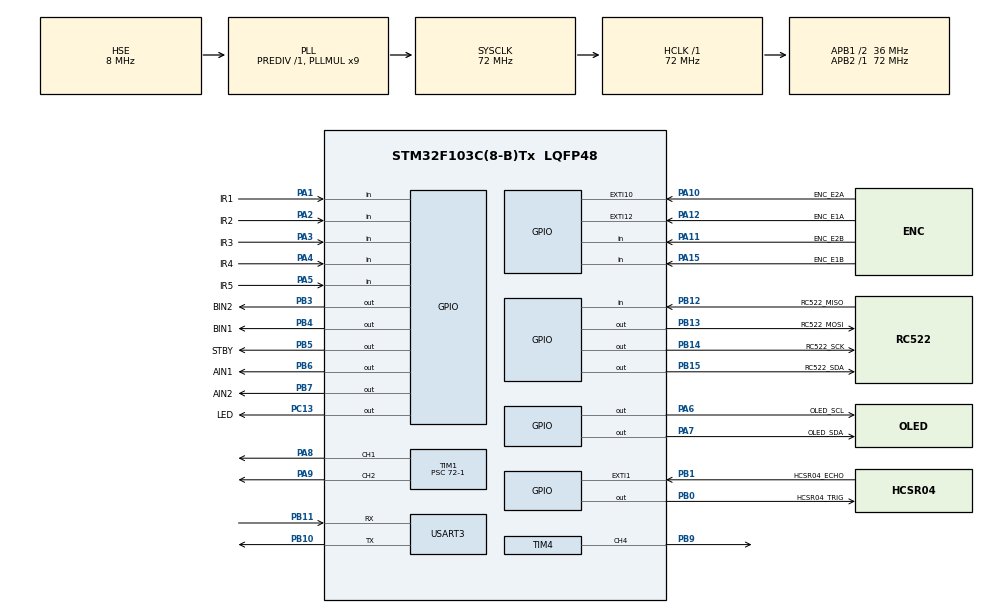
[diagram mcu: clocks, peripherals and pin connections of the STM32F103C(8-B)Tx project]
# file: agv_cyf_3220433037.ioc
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Mcu.Family=STM32F1
Mcu.Name=STM32F103C(8-B)Tx
Mcu.Package=LQFP48
NVIC.EXTI1_IRQn=true\:1\:0\:false\:false\:true\:true\:false\:false
NVIC.EXTI15_10_IRQn=true\:2\:0\:false\:false\:true\:true\:false\:false
NVIC.PriorityGroup=NVIC_PRIORITYGROUP_4
NVIC.USART3_IRQn=true\:1\:0\:false\:false\:true\:true\:false\:false
PA1.GPIO_Label=IR1
PA1.GPIO_PuPd=GPIO_PULLUP
PA1.Signal=GPIO_Input
PA10.GPIO_Label=ENC_E2A
PA10.GPIO_ModeDefaultEXTI=GPIO_MODE_IT_RISING_FALLING
PA10.GPIO_PuPd=GPIO_PULLUP
PA10.Signal=GPXTI10
PA11.GPIO_Label=ENC_E2B
PA11.GPIO_PuPd=GPIO_PULLUP
PA11.Signal=GPIO_Input
PA12.GPIO_Label=ENC_E1A
PA12.GPIO_ModeDefaultEXTI=GPIO_MODE_IT_RISING_FALLING
PA12.GPIO_PuPd=GPIO_PULLUP
PA12.Signal=GPXTI12
PA13.Mode=Serial_Wire
PA13.Signal=SYS_JTMS-SWDIO
PA14.Mode=Serial_Wire
PA14.Signal=SYS_JTCK-SWCLK
PA15.GPIO_Label=ENC_E1B
PA15.GPIO_PuPd=GPIO_PULLUP
PA15.Signal=GPIO_Input
PA2.GPIO_Label=IR2
PA2.GPIO_PuPd=GPIO_PULLUP
PA2.Signal=GPIO_Input
PA3.GPIO_Label=IR3
PA3.GPIO_PuPd=GPIO_PULLUP
PA3.Signal=GPIO_Input
PA4.GPIO_Label=IR4
PA4.GPIO_PuPd=GPIO_PULLUP
PA4.Signal=GPIO_Input
PA5.GPIO_Label=IR5
PA5.GPIO_PuPd=GPIO_PULLUP
PA5.Signal=GPIO_Input
PA6.GPIO_Label=OLED_SCL
PA6.GPIO_ModeDefaultOutputPP=GPIO_MODE_OUTPUT_OD
PA6.GPIO_PuPd=GPIO_PULLUP
PA6.PinState=GPIO_PIN_SET
PA6.Signal=GPIO_Output
PA7.GPIO_Label=OLED_SDA
PA7.GPIO_ModeDefaultOutputPP=GPIO_MODE_OUTPUT_OD
PA7.GPIO_PuPd=GPIO_PULLUP
PA7.PinState=GPIO_PIN_SET
PA7.Signal=GPIO_Output
PA8.Signal=S_TIM1_CH1
PA9.Signal=S_TIM1_CH2
PB0.GPIO_Label=HCSR04_TRIG
PB0.Signal=GPIO_Output
PB1.GPIO_Label=HCSR04_ECHO
PB1.GPIO_ModeDefaultEXTI=GPIO_MODE_IT_RISING_FALLING
PB1.GPIO_PuPd=GPIO_NOPULL
PB1.Signal=GPXTI1
PB10.Mode=Asynchronous
PB10.Signal=USART3_TX
PB11.Mode=Asynchronous
PB11.Signal=USART3_RX
PB12.GPIO_Label=RC522_MISO
PB12.GPIO_PuPd=GPIO_NOPULL
PB12.Signal=GPIO_Input
PB13.GPIO_Label=RC522_MOSI
PB13.GPIO_ModeDefaultOutputPP=GPIO_MODE_OUTPUT_PP
PB13.GPIO_PuPd=GPIO_NOPULL
PB13.PinState=GPIO_PIN_RESET
PB13.Signal=GPIO_Output
PB14.GPIO_Label=RC522_SCK
PB14.GPIO_ModeDefaultOutputPP=GPIO_MODE_OUTPUT_PP
PB14.GPIO_PuPd=GPIO_NOPULL
PB14.PinState=GPIO_PIN_RESET
PB14.Signal=GPIO_Output
PB15.GPIO_Label=RC522_SDA
PB15.GPIO_ModeDefaultOutputPP=GPIO_MODE_OUTPUT_PP
PB15.GPIO_PuPd=GPIO_NOPULL
PB15.PinState=GPIO_PIN_SET
PB15.Signal=GPIO_Output
PB3.GPIO_Label=BIN2
PB3.Signal=GPIO_Output
PB4.GPIO_Label=BIN1
PB4.Signal=GPIO_Output
PB5.GPIO_Label=STBY
PB5.Signal=GPIO_Output
PB6.GPIO_Label=AIN1
PB6.Signal=GPIO_Output
PB7.GPIO_Label=AIN2
PB7.Signal=GPIO_Output
PB9.Signal=S_TIM4_CH4
PC13-TAMPER-RTC.GPIO_Label=LED
PC13-TAMPER-RTC.GPIO_ModeDefaultOutputPP=GPIO_MODE_OUTPUT_PP
PC13-TAMPER-RTC.GPIO_PuPd=GPIO_NOPULL
PC13-TAMPER-RTC.PinState=GPIO_PIN_SET
PC13-TAMPER-RTC.Signal=GPIO_Output
PD0-OSC_IN.Mode=HSE-External-Oscillator
PD0-OSC_IN.Signal=RCC_OSC_IN
PD1-OSC_OUT.Mode=HSE-External-Oscillator
PD1-OSC_OUT.Signal=RCC_OSC_OUT
ProjectManager.HeapSize=0x200
ProjectManager.StackSize=0x400
ProjectManager.TargetToolchain=MDK-ARM V5.32
RCC.AHBFreq_Value=72000000
RCC.APB1CLKDivider=RCC_HCLK_DIV2
RCC.APB1Freq_Value=36000000
RCC.APB1TimFreq_Value=72000000
RCC.APB2Freq_Value=72000000
RCC.APB2TimFreq_Value=72000000
RCC.HCLKFreq_Value=72000000
RCC.PLLMUL=RCC_PLL_MUL9
RCC.PLLSourceVirtual=RCC_PLLSOURCE_HSE
RCC.SYSCLKFreq_VALUE=72000000
RCC.SYSCLKSource=RCC_SYSCLKSOURCE_PLLCLK
RCC.USBFreq_Value=72000000
SH.S_TIM1_CH1.0=TIM1_CH1,PWM Generation1 CH1
SH.S_TIM1_CH2.0=TIM1_CH2,PWM Generation2 CH2
SH.S_TIM4_CH4.0=TIM4_CH4,PWM Generation4 CH4
TIM1.Channel-PWM\ Generation1\ CH1=TIM_CHANNEL_1
TIM1.Channel-PWM\ Generation2\ CH2=TIM_CHANNEL_2
TIM1.Period=1000-1
TIM1.Prescaler=72-1
TIM2.Period=65535
TIM2.Prescaler=72-1
TIM4.Channel-PWM\ Generation4\ CH4=TIM_CHANNEL_4
TIM4.Period=20000-1
TIM4.Prescaler=72-1
USART3.VirtualMode=VM_ASYNC
VP_TIM1_VS_ClockSourceINT.Mode=Internal
VP_TIM2_VS_ClockSourceINT.Mode=Internal
VP_TIM4_VS_ClockSourceINT.Mode=Internal
board=custom

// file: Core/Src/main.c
/* USER CODE BEGIN Header */
/**
  ******************************************************************************
  * @file           : main.c
  * @brief          : Main program body
  ******************************************************************************
  * @attention
  *
  * Copyright (c) 2026 STMicroelectronics.
  * All rights reserved.
  *
  * This software is licensed under terms that can be found in the LICENSE file
  * in the root directory of this software component.
  * If no LICENSE file comes with this software, it is provided AS-IS.
  *
  ******************************************************************************
  */
/* USER CODE END Header */
#include "main.h"
#include "tim.h"
#include "usart.h"
#include "gpio.h"

/* USER CODE BEGIN Includes */
#include "app_encoder.h"
#include "app_ultrasonic.h"
#include "app_vehicle.h"
/*
 * main.c 的职责很单一：
 * 1. 完成 HAL、时钟和基础外设初始化；
 * 2. 初始化上层整车应用模块；
 * 3. 在死循环中反复调用 AppVehicle_Task()。
 *
 * 也就是说，真正的业务逻辑不写在 main 里，而是统一交给
 * app_vehicle 模块调度，这样后续维护状态机时更集中。
 */
/* USER CODE END Includes */

void SystemClock_Config(void);

int main(void)
{
  /*
   * 先初始化 HAL 和系统时钟。
   * HAL_Init() 会初始化 SysTick 等基础环境；
   * SystemClock_Config() 决定 MCU 后续运行频率。
   */
  HAL_Init();
  SystemClock_Config();

  /*
   * 初始化本工程用到的底层外设。
   * 这些函数由 CubeMX 生成，负责把 GPIO、定时器、串口配置到可用状态。
   */
  MX_GPIO_Init();
  MX_TIM1_Init();
  MX_TIM2_Init();
  MX_TIM4_Init();
  MX_USART3_UART_Init();

  /* 初始化整车应用层，包括状态机、传感器和执行器的上层封装。 */
  AppVehicle_Init();

  while (1)
  {
    /*
     * 主循环采用“协作式轮询”模型：
     * 不开 RTOS，不做任务切换，而是不断调用统一任务入口，
     * 由 AppVehicle_Task() 在内部决定当前时刻该处理什么。
     */
    AppVehicle_Task();
  }
}

void SystemClock_Config(void)
{
  RCC_OscInitTypeDef RCC_OscInitStruct = {0};
  RCC_ClkInitTypeDef RCC_ClkInitStruct = {0};

  /*
   * 使用外部高速晶振 HSE，经 PLL 倍频后得到 72MHz 系统主频。
   * 这是 STM32F103 常见的运行配置，兼顾性能和外设时序。
   */
  RCC_OscInitStruct.OscillatorType = RCC_OSCILLATORTYPE_HSE;
  RCC_OscInitStruct.HSEState = RCC_HSE_ON;
  RCC_OscInitStruct.HSEPredivValue = RCC_HSE_PREDIV_DIV1;
  RCC_OscInitStruct.HSIState = RCC_HSI_ON;
  RCC_OscInitStruct.PLL.PLLState = RCC_PLL_ON;
  RCC_OscInitStruct.PLL.PLLSource = RCC_PLLSOURCE_HSE;
  RCC_OscInitStruct.PLL.PLLMUL = RCC_PLL_MUL9;
  if (HAL_RCC_OscConfig(&RCC_OscInitStruct) != HAL_OK)
  {
    Error_Handler();
  }

  RCC_ClkInitStruct.ClockType = RCC_CLOCKTYPE_HCLK | RCC_CLOCKTYPE_SYSCLK |
                                RCC_CLOCKTYPE_PCLK1 | RCC_CLOCKTYPE_PCLK2;
  RCC_ClkInitStruct.SYSCLKSource = RCC_SYSCLKSOURCE_PLLCLK;
  RCC_ClkInitStruct.AHBCLKDivider = RCC_SYSCLK_DIV1;
  RCC_ClkInitStruct.APB1CLKDivider = RCC_HCLK_DIV2;
  RCC_ClkInitStruct.APB2CLKDivider = RCC_HCLK_DIV1;

  if (HAL_RCC_ClockConfig(&RCC_ClkInitStruct, FLASH_LATENCY_2) != HAL_OK)
  {
    Error_Handler();
  }
}

/* USER CODE BEGIN 4 */
void HAL_GPIO_EXTI_Callback(uint16_t GPIO_Pin)
{
  /*
   * HAL 会在任意 EXTI 引脚中断触发后回调这里。
   * 这里不直接写业务，而是按模块分发：
   * - 超声波模块处理 ECHO 回波边沿
   * - 编码器模块处理 AB 相中的 A 相边沿
   */
  AppUltrasonic_HandleEchoExti(GPIO_Pin);
  AppEncoder_HandleExti(GPIO_Pin);
}
/* USER CODE END 4 */

void Error_Handler(void)
{
  __disable_irq();
  while (1)
  {
  }
}
